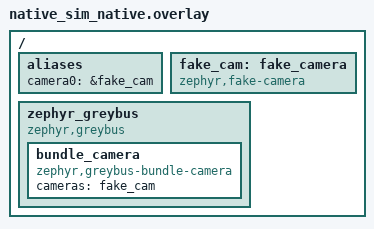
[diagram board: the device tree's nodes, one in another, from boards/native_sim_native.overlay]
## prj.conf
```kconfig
CONFIG_ZTEST=y
CONFIG_VIDEO=y
CONFIG_FAKE_CAMERA=y
CONFIG_LOG=y
CONFIG_GREYBUS=y
CONFIG_GREYBUS_LOG_LEVEL_DBG=y
CONFIG_VIDEO_BUFFER_POOL_HEAP_SIZE=32768
CONFIG_VIDEO_BUFFER_POOL_NUM_MAX=4
CONFIG_GREYBUS_CAMERA=y
```

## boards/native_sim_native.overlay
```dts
/ {
    aliases {
        camera0 = &fake_cam;
    };

    fake_cam: fake_camera {
        compatible = "zephyr,fake-camera";
        status = "okay";
    };

    zephyr_greybus {
        compatible = "zephyr,greybus";
        status = "okay";
        
        bundle_camera: bundle_camera {
            compatible = "zephyr,greybus-bundle-camera";
            status = "okay";
            cameras = <&fake_cam>; 
        };
    };
};
```

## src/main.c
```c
/*
 * Copyright (c) 2026 Pavithra CP, BeagleBoard.org
 *
 * SPDX-License-Identifier: Apache-2.0
 */
#include <greybus/greybus_messages.h>
#include <greybus/greybus_protocols.h>
#include <greybus/greybus.h>
#include <zephyr/ztest.h>
#include <zephyr/kernel.h>
#include <zephyr/device.h>
#include <zephyr/sys/byteorder.h>
#include <zephyr/logging/log.h>
#include <zephyr/fff.h>

DEFINE_FFF_GLOBALS;
LOG_MODULE_REGISTER(greybus_camera_test, CONFIG_GREYBUS_LOG_LEVEL);

struct gb_msg_with_cport gb_transport_get_message(void);

static const int camera_cport = 1;

static void *camera_setup(void)
{
	struct gb_msg_with_cport resp;
	struct gb_message *msg;
	struct gb_control_version_request *ver_req;
	struct gb_control_connected_request *conn_req;

	msg = gb_message_request_alloc(sizeof(*ver_req), GB_CONTROL_TYPE_VERSION, false);
	ver_req = (struct gb_control_version_request *)msg->payload;
	ver_req->major = 0;
	ver_req->minor = 1;

	greybus_rx_handler(0, msg);
	resp = gb_transport_get_message();
	zassert_not_null(resp.msg, "No version response received");
	zassert_true(gb_message_is_success(resp.msg), "Version Handshake failed");
	gb_message_dealloc(resp.msg);

	msg = gb_message_request_alloc(sizeof(*conn_req), GB_CONTROL_TYPE_CONNECTED, false);
	conn_req = (struct gb_control_connected_request *)msg->payload;
	conn_req->cport_id = sys_cpu_to_le16(camera_cport);

	greybus_rx_handler(0, msg);
	resp = gb_transport_get_message();
	zassert_not_null(resp.msg, "No connect response received");
	zassert_true(gb_message_is_success(resp.msg), "CPort Connection failed");
	gb_message_dealloc(resp.msg);

	return NULL;
}

ZTEST_SUITE(greybus_camera_tests, NULL, camera_setup, NULL, NULL, NULL);

ZTEST(greybus_camera_tests, test_attempt_premature_capture)
{
	struct gb_msg_with_cport resp;
	struct gb_message *req;
	struct gb_camera_capture_request *cap_req;

	req = gb_message_request_alloc(sizeof(*cap_req), GB_CAMERA_TYPE_CAPTURE, false);
	cap_req = (struct gb_camera_capture_request *)req->payload;
	cap_req->num_frames = sys_cpu_to_le16(1);

	greybus_rx_handler(camera_cport, req);
	resp = gb_transport_get_message();

	zassert_not_null(resp.msg, "No capture response received");
	zassert_equal(resp.msg->header.result, GB_OP_INVALID,
		      "Expected GB_OP_INVALID for premature capture, got: %d",
		      resp.msg->header.result);

	gb_message_dealloc(resp.msg);
}

ZTEST(greybus_camera_tests, test_bad_configure_zero_res)
{
	struct gb_message *req;
	struct gb_msg_with_cport resp;
	struct gb_camera_configure_streams_request *cfg_req;
	size_t payload_size = sizeof(*cfg_req) + sizeof(struct gb_camera_stream_config_request);

	req = gb_message_request_alloc(payload_size, GB_CAMERA_TYPE_CONFIGURE_STREAMS, false);
	cfg_req = (struct gb_camera_configure_streams_request *)req->payload;
	cfg_req->num_streams = 1;
	cfg_req->config[0].width = sys_cpu_to_le16(0);
	cfg_req->config[0].height = sys_cpu_to_le16(480);

	greybus_rx_handler(camera_cport, req);
	resp = gb_transport_get_message();

	zassert_not_null(resp.msg, "No config response received");
	zassert_equal(resp.msg->header.result, GB_OP_INVALID,
		      "Expected GB_OP_INVALID for 0x480 resolution, got: %d",
		      resp.msg->header.result);

	gb_message_dealloc(resp.msg);
}

ZTEST(greybus_camera_tests, test_configure_valid)
{
	struct gb_message *req;
	struct gb_msg_with_cport resp;
	struct gb_camera_configure_streams_request *cfg_req;

	size_t payload_size = sizeof(struct gb_camera_configure_streams_request) +
			      sizeof(struct gb_camera_stream_config_request);

	req = gb_message_request_alloc(payload_size, GB_CAMERA_TYPE_CONFIGURE_STREAMS, false);
	cfg_req = (struct gb_camera_configure_streams_request *)req->payload;
	cfg_req->num_streams = 1;

	/* --- FIX: Lower resolution so the 4KB memory pool is accepted --- */
	cfg_req->config[0].width = sys_cpu_to_le16(32);
	cfg_req->config[0].height = sys_cpu_to_le16(32);
	/* ---------------------------------------------------------------- */

	cfg_req->config[0].format = sys_cpu_to_le16(1);

	greybus_rx_handler(camera_cport, req);
	resp = gb_transport_get_message();

	zassert_not_null(resp.msg, "No config response received");
	zassert_true(gb_message_is_success(resp.msg), "Valid Config failed: %d",
		     resp.msg->header.result);

	gb_message_dealloc(resp.msg);
}

ZTEST(greybus_camera_tests, test_flush_prematurely)
{
	struct gb_msg_with_cport resp;
	struct gb_message *req;

	req = gb_message_request_alloc(0, GB_CAMERA_TYPE_FLUSH, false);

	greybus_rx_handler(camera_cport, req);
	resp = gb_transport_get_message();

	zassert_not_null(resp.msg, "No flush response received");
	zassert_equal(resp.msg->header.result, GB_OP_INVALID,
		      "Expected GB_OP_INVALID for premature flush, got: %d",
		      resp.msg->header.result);

	gb_message_dealloc(resp.msg);
}

ZTEST(greybus_camera_tests, test_garbage_capture_payload)
{
	struct gb_msg_with_cport resp;
	struct gb_message *req;
	struct gb_camera_capture_request *cap_req;

	size_t bad_payload_size = sizeof(*cap_req) + 1;

	req = gb_message_request_alloc(bad_payload_size, GB_CAMERA_TYPE_CAPTURE, false);
	cap_req = (struct gb_camera_capture_request *)req->payload;
	cap_req->num_frames = sys_cpu_to_le16(1);

	greybus_rx_handler(camera_cport, req);
	resp = gb_transport_get_message();

	zassert_not_null(resp.msg, "No capture response received");
	zassert_equal(resp.msg->header.result, GB_OP_INVALID,
		      "Expected GB_OP_INVALID for malformed payload, got: %d",
		      resp.msg->header.result);

	gb_message_dealloc(resp.msg);
}

ZTEST(greybus_camera_tests, test_valid_01_capture)
{
	struct gb_msg_with_cport resp;
	struct gb_message *req;
	struct gb_camera_capture_request *cap_req;

	req = gb_message_request_alloc(sizeof(*cap_req), GB_CAMERA_TYPE_CAPTURE, false);
	cap_req = (struct gb_camera_capture_request *)req->payload;
	cap_req->num_frames = sys_cpu_to_le16(10);

	greybus_rx_handler(camera_cport, req);
	resp = gb_transport_get_message();

	zassert_not_null(resp.msg, "No capture response received");
	zassert_true(gb_message_is_success(resp.msg), "Valid Capture failed: %d",
		     resp.msg->header.result);

	gb_message_dealloc(resp.msg);
}

ZTEST(greybus_camera_tests, test_valid_02_data_wait)
{

	struct gb_msg_with_cport resp;

	for (int i = 0; i < 2; i++) {
		resp = gb_transport_get_message();

		zassert_not_null(resp.msg, "Received null message!");
		zassert_equal(resp.msg->header.type, 0x00, "Expected Data packet (type 0), got: %d",
			      resp.msg->header.type);

		gb_message_dealloc(resp.msg);
	}
}

ZTEST(greybus_camera_tests, test_valid_03_flush)
{
	struct gb_msg_with_cport resp;
	struct gb_message *req;
	const struct gb_camera_flush_response *flush_resp;
	bool flush_response_received = false;

	req = gb_message_request_alloc(0, GB_CAMERA_TYPE_FLUSH, false);
	greybus_rx_handler(camera_cport, req);

	for (int i = 0; i < 50; i++) {
		resp = gb_transport_get_message();

		if (resp.msg == NULL) {
			k_msleep(10);
			continue;
		}

		if (resp.msg->header.type == 0x00) {
			gb_message_dealloc(resp.msg);
			continue;
		}

		zassert_true(gb_message_is_success(resp.msg), "Valid Flush failed: %d",
			     resp.msg->header.result);

		flush_resp = (struct gb_camera_flush_response *)resp.msg->payload;
		zassert_equal(flush_resp->request_id, sys_cpu_to_le32(1),
			      "Expected stubbed request_id of 1");
		// expected 1 after processing the previous frame

		gb_message_dealloc(resp.msg);
		flush_response_received = true;
		break;
	}

	zassert_true(flush_response_received, "Queue drained but never received flush response!");
}
```
